# IMM100A register map
Vendor: Infineon; File version: 0.8.0 (Reference Manual v0.8.0)
CPU: CM0 r0p0, little endian, no MPU, no FPU, 2 interrupt priority bits
Registers are 32-bit, read-write, reset 0x0 unless marked. A register's access mark holds for its fields unless they carry their own. Offsets are from the block's base; [hi:lo] are bit positions; lines under a group give offsets from that group; {n}, {i} and the like mark numbered series; 'fields as' and 'values as' point back to an identical list.

## VADC_G0 — Analog to Digital Converter
Base 0x48030400
Same registers: VADC_G1 0x48030800
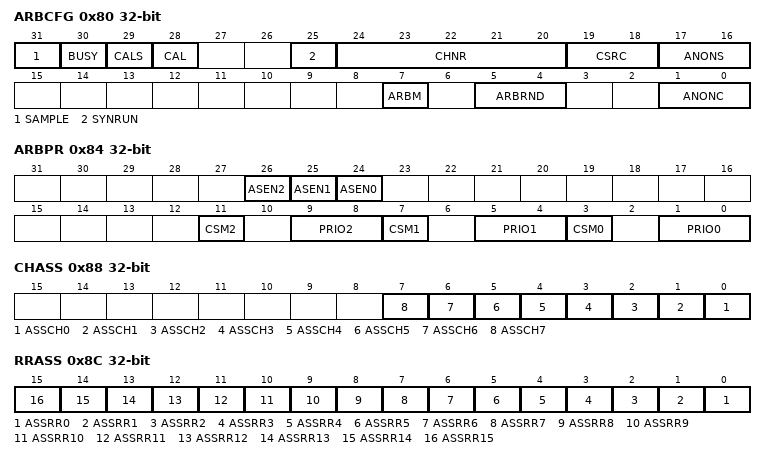
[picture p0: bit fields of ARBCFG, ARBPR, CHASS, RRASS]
0x80 ARBCFG access per field — Arbitration Configuration Register
  [31] SAMPLE ro — Sample Phase Flag
    0=Converting or idle; 1=Input signal is currently sampled
  [30] BUSY ro — Converter Busy Flag
    0=Not busy; 1=Converter is busy with a conversion
  [29] CALS ro — Start-Up Calibration Started
    0=Requested but not yet started; 1=Start-up calibration has begun
  [28] CAL ro — Start-Up Calibration Active Indication
    0=Completed or not yet started; 1=Start-up calibration phase is active (set one clock cycle after setting bit SUCAL)
  [25] SYNRUN ro — Synchronous Conversion Running
    0=Normal conversion or no conversion running; 1=A synchronized conversion is running (cannot be cancelled by higher priority requests!)
  [24:20] CHNR ro — Channel Number
  [19:18] CSRC ro — Currently Converted Request Source
    0=Current/last conversion for request source 0; 1=Current/last conversion for request source 1; 2=Current/last conversion for background source; 3=Current/last conversion for synchronization request (slave converter)
  [17:16] ANONS ro — Analog Converter Control Status
    0=Analog converter off; 2=Slow standby mode; 3=Normal operation (permanently on)
  [7] ARBM rw — Arbitration Mode
    0=The arbiter runs permanently. This setting is required for a synchronization slave (see ) and for equidistant sampling using the signal ARBCNT (see ).; 1=The arbiter only runs if at least one conversion request of an enabled request source is pending. This setting ensures a reproducible latency from an incoming request to the conversion start, if the converter is idle. Synchronized conversions are not supported.
  [5:4] ARBRND rw — Arbitration Round Length
    0=4 arbitration slots per round (tARB = 4 / fADCD); 1=8 arbitration slots per round (tARB = 8 / fADCD); 2=16 arbitration slots per round (tARB = 16 / fADCD); 3=20 arbitration slots per round (tARB = 20 / fADCD)
  [1:0] ANONC rw — Analog Converter Control
0x84 ARBPR — Arbitration Priority Register
  [26] ASEN2 — Arbitration Slot 2 Enable
    0=The corresponding arbitration slot is disabled and considered as empty. Pending conversion requests from the associated request source are disregarded.; 1=The corresponding arbitration slot is enabled. Pending conversion requests from the associated request source are arbitrated.
  [25] ASEN1 — Arbitration Slot 1 Enable
    values as ASEN2
  [24] ASEN0 — Arbitration Slot 0 Enable
    values as ASEN2
  [11] CSM2 — Conversion Start Mode of Request Source x
    0=Wait-for-start mode; 1=Cancel-inject-repeat mode, i.e. this source can cancel conversion of other sources.
  [9:8] PRIO2 — Priority of Request Source x
    0=Lowest priority is selected; 3=Highest priority is selected
  [7] CSM1 — Conversion Start Mode of Request Source x
    values as CSM2
  [5:4] PRIO1 — Priority of Request Source x
    values as PRIO2
  [3] CSM0 — Conversion Start Mode of Request Source x
    values as CSM2
  [1:0] PRIO0 — Priority of Request Source x
    values as PRIO2
0x88 CHASS — Channel Assignment Register
  [all] fields
    0=Channel y can be a background channel converted with lowest priority; 1=Channel y is a priority channel within group x
  [n] ASSCH{n} (n=0..7) — Assignment for Channel {n}
0x8C RRASS — Result Assignment Register
  [all] fields
    0=Result register y can also be written by the background source; 1=Result register y can only be written by sources within group x
  [n] ASSRR{n} (n=0..15) — Assignment for Result Register {n}
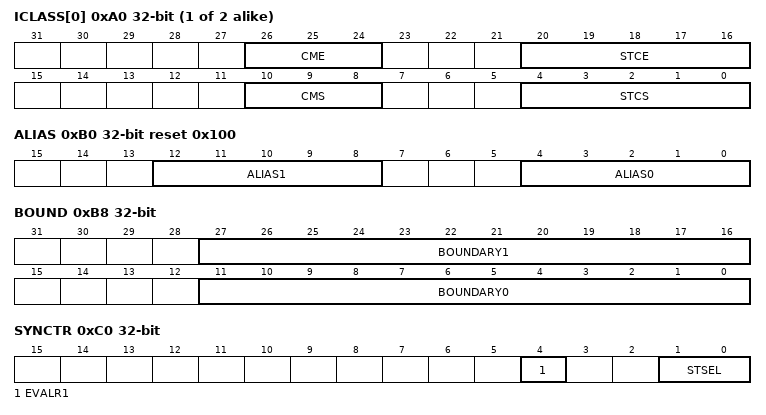
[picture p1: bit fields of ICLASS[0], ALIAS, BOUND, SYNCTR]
{0xA0+4i} ICLASS[{i}] (i=0..1) — Input Class Register 0
  [26:24] CME — Conversion Mode for EMUX Conversions
    0=12-bit conversion; 1=10-bit conversion; 2=8-bit conversion; 5=10-bit fast compare mode
  [20:16] STCE — Sample Time Control for EMUX Conversions
  [10:8] CMS — Conversion Mode for Standard Conversions
    values as CME
  [4:0] STCS — Sample Time Control for Standard Conversions
0xB0 ALIAS reset 0x100
  [12:8] ALIAS1 — Alias Value for CH1 Conversion Requests
  [4:0] ALIAS0 — Alias Value for CH0 Conversion Requests
0xB8 BOUND — Boundary Select Register
  [27:16] BOUNDARY1 — Boundary Value 1 for Limit Checking
  [11:0] BOUNDARY0 — Boundary Value 0 for Limit Checking
0xC0 SYNCTR — Synchronization Control Register
  [4] EVALR1 — Evaluate Ready Input R1
    0=No ready input control; 1=Ready input R1 is considered for the start of a parallel conversion of this conversion group
  [1:0] STSEL — Start Selection
    0=Kernel is synchronization master: Use own bitfield GxARBCFG.ANONC; 1=Kernel is synchronization slave: Control information from input CI1
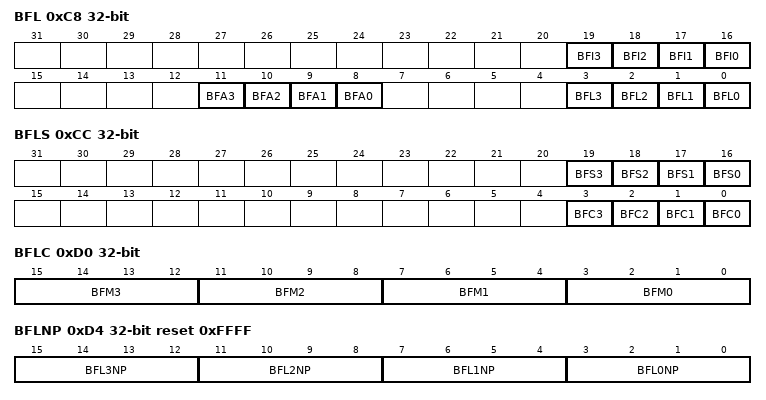
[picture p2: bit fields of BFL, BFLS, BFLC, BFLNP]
0xC8 BFL access per field — Boundary Flag Register
  [n+16] BFI{n} rw (n=0..3) — Boundar{n} Flag y Inversion Control
    0=Use BFLy directly; 1=Invert value and use BFLy
  [n+8] BFA{n} rw (n=0..3) — Boundar{n} Flag y Activation Select
    0=Set boundary flag BFLy if result is above the defined band or compare value, clear if below; 1=Set boundary flag BFLy if result is below the defined band or compare value, clear if above
  [n] BFL{n} ro (n=0..3) — Boundar{n} Flag y
    0=Passive state: result has not yet crossed the activation boundary (see bitfield BFAy), or selected gate signal is inactive, or this boundary flag is disabled; 1=Active state: result has crossed the activation boundary
0xCC BFLS wo — Boundary Flag Software Register
  [n+16] BFS{n} (n=0..3) — Boundar{n} Flag y Set
    0=No action; 1=Set bit BFLy
  [n] BFC{n} (n=0..3) — Boundar{n} Flag y Clear
    0=No action; 1=Clear bit BFLy
0xD0 BFLC — Boundary Flag Control Register
  [all] fields
    0=Disable boundary flag, BFLy is not changed; 1=Always enable boundary flag (follow compare results); 2=Enable boundary flag while gate of source 0 is active, clear BFLy while gate is inactive; 3=Enable boundary flag while gate of source 1 is active, clear BFLy while gate is inactive
  [4n+3:4n] BFM{n} (n=0..3) — Boundary Flag y Mode Control
0xD4 BFLNP reset 0xFFFF — Boundary Flag Node Pointer Register
  [all] fields
    0=Select common bondary flag output 0; 3=Select common bondary flag output 3; 4=Select common service request line C0SR0; 7=Select common service request line C0SR3; 15=Disabled, no common output signal
  [4n+3:4n] BFL{n}NP (n=0..3) — Boundary Flag y Node Pointer
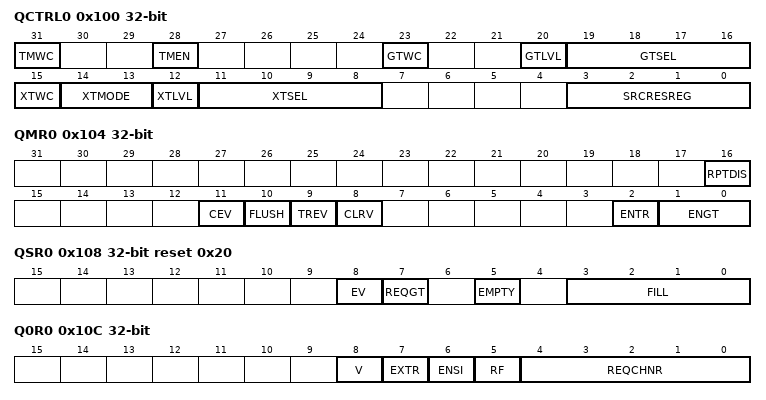
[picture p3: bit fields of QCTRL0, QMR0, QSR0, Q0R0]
0x100 QCTRL0 access per field — Queue 0 Source Control Register
  [31] TMWC wo — Write Control for Timer Mode
    0=No write access to timer mode; 1=Bitfield TMEN can be written
  [28] TMEN rw — Timer Mode Enable
    0=No timer mode: standard gating mechanism can be used; 1=Timer mode for equidistant sampling enabled: standard gating mechanism must be disabled
  [23] GTWC wo — Write Control for Gate Configuration
    0=No write access to gate configuration; 1=Bitfield GTSEL can be written
  [20] GTLVL ro — Gate Input Level
  [19:16] GTSEL rw — Gate Input Selection
  [15] XTWC wo — Write Control for Trigger Configuration
    0=No write access to trigger configuration; 1=Bitfields XTMODE and XTSEL can be written
  [14:13] XTMODE rw — Trigger Operating Mode
    0=No external trigger; 1=Trigger event upon a falling edge; 2=Trigger event upon a rising edge; 3=Trigger event upon any edge
  [12] XTLVL ro — External Trigger Level
  [11:8] XTSEL rw — External Trigger Input Selection
  [3:0] SRCRESREG rw — Source-specific Result Register
    0=Use GxCHCTRy.RESREG to select a group result register; 1=Store result in group result register GxRES1; 15=Store result in group result register GxRES15
0x104 QMR0 access per field — Queue 0 Mode Register
  [16] RPTDIS rw — Repeat Disable
    0=A cancelled conversion is repeated; 1=A cancelled conversion is discarded
  [11] CEV wo — Clear Event Flag
    0=No action; 1=Clear bit EV
  [10] FLUSH wo — Flush Queue
    0=No action; 1=Clear all queue entries (including backup stage) and the event flag EV. The queue contains no more valid entry.
  [9] TREV wo — Trigger Event
    0=No action; 1=Generate a trigger event by software
  [8] CLRV wo — Clear Valid Bit
    0=No action; 1=The next pending valid queue entry in the sequence and the event flag EV are cleared. If there is a valid entry in the queue backup register (QBUR.V = 1), this entry is cleared, otherwise the entry in queue register 0 is cleared.
  [2] ENTR rw — Enable External Trigger
    0=External trigger disabled; 1=The selected edge at the selected trigger input signal REQTR generates the trigger event
  [1:0] ENGT rw — Enable Gate
    0=No conversion requests are issued; 1=Conversion requests are issued if a valid conversion request is pending in the queue 0 register or in the backup register; 2=Conversion requests are issued if a valid conversion request is pending in the queue 0 register or in the backup register and REQGTx = 1; 3=Conversion requests are issued if a valid conversion request is pending in the queue 0 register or in the backup register and REQGTx = 0
0x108 QSR0 ro reset 0x20 — Queue 0 Status Register
  [8] EV — Event Detected
    0=No trigger event; 1=A trigger event has been detected
  [7] REQGT — Request Gate Level
    0=The gate input is low; 1=The gate input is high
  [5] EMPTY — Queue Empty
    0=There are valid entries in the queue (see FILL); 1=No valid entries (queue is empty)
  [3:0] FILL — Filling Level for Queue 2
    0=There is 1 ( if EMPTY = 0) or no (if EMPTY = 1) valid entry in the queue; 1=There are 2 valid entries in the queue; 2=There are 3 valid entries in the queue; 7=There are 8 valid entries in the queue
0x10C Q0R0 ro — Queue 0 Register 0
  [8] V — Request Channel Number Valid
    0=No valid queue entry; 1=The queue entry is valid and leads to a conversion request
  [7] EXTR — External Trigger
    0=A valid queue entry immediately leads to a conversion request; 1=The request handler waits for a trigger event
  [6] ENSI — Enable Source Interrupt
    0=No request source interrupt; 1=A request source event interrupt is generated upon a request source event (related conversion is finished)
  [5] RF — Refill
    0=The request is discarded after the conversion start; 1=The request is automatically refilled into the queue after the conversion start
  [4:0] REQCHNR — Request Channel Number
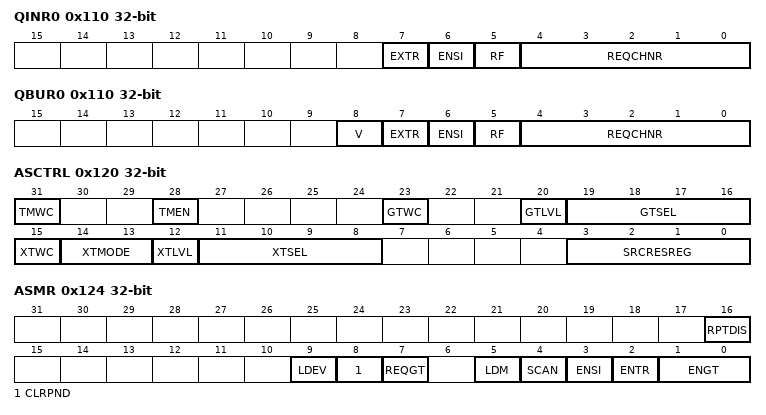
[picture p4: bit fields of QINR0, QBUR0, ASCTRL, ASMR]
0x110 QINR0 wo — Queue 0 Input Register
  [7] EXTR — External Trigger
    0=A valid queue entry immediately leads to a conversion request; 1=A valid queue entry waits for a trigger event to occur before issuing a conversion request
  [6] ENSI — Enable Source Interrupt
    values as Q0R0.ENSI
  [5] RF — Refill
    0=No refill: this queue entry is converted once and then invalidated; 1=Automatic refill: this queue entry is automatically reloaded into QINRx when the related conversion is started
  [4:0] REQCHNR — Request Channel Number
0x110 QBUR0 ro (alternate view of QINR0) — Queue 0 Backup Register
  [8] V — Request Channel Number Valid
    0=Backup register not valid; 1=Backup register contains a valid entry. This will be requested before a valid entry in queue register 0 (stage 0) will be requested.
  [7] EXTR — External Trigger
  [6] ENSI — Enable Source Interrupt
  [5] RF — Refill
  [4:0] REQCHNR — Request Channel Number
0x120 ASCTRL access per field — Autoscan Source Control Register
  fields as QCTRL0
0x124 ASMR access per field — Autoscan Source Mode Register
  [16] RPTDIS rw — Repeat Disable
    values as QMR0.RPTDIS
  [9] LDEV wo — Generate Load Event
    0=No action; 1=A load event is generated
  [8] CLRPND wo — Clear Pending Bits
    0=No action; 1=The bits in register GxASPNDx are cleared
  [7] REQGT ro — Request Gate Level
    0=The gate input is low; 1=The gate input is high
  [5] LDM rw — Autoscan Source Load Event Mode
    0=Overwrite mode: Copy all bits from the select registers to the pending registers upon a load event; 1=Combine mode: Set all pending bits that are set in the select registers upon a load event (logic OR)
  [4] SCAN rw — Autoscan Enable
    0=No autoscan; 1=Autoscan functionality enabled: a request source event automatically generates a load event
  [3] ENSI rw — Enable Source Interrupt
    0=No request source interrupt; 1=A request source interrupt is generated upon a request source event (last pending conversion is finished)
  [2] ENTR rw — Enable External Trigger
    0=External trigger disabled; 1=The selected edge at the selected trigger input signal REQTR generates the load event
  [1:0] ENGT rw — Enable Gate
    0=No conversion requests are issued; 1=Conversion requests are issued if at least one pending bit is set; 2=Conversion requests are issued if at least one pending bit is set and REQGTx = 1; 3=Conversion requests are issued if at least one pending bit is set and REQGTx = 0
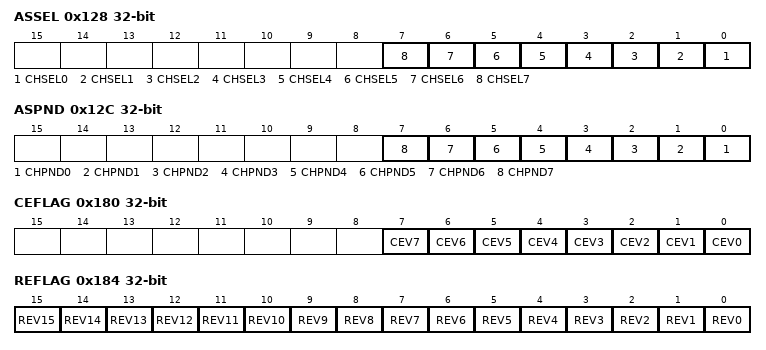
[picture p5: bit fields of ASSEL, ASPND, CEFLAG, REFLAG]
0x128 ASSEL — Autoscan Source Channel Select Register
  [all] fields
    0=Ignore this channel; 1=This channel is part of the scan sequence
  [n] CHSEL{n} (n=0..7) — Channel Selection
0x12C ASPND — Autoscan Source Pending Register
  [all] fields
    0=Ignore this channel; 1=Request conversion of this channel
  [n] CHPND{n} (n=0..7) — Channels Pending
0x180 CEFLAG — Channel Event Flag Register
  [all] fields
    0=No channel event; 1=A channel event has occurred
  [n] CEV{n} (n=0..7) — Channel Event for Channel {n}
0x184 REFLAG — Result Event Flag Register
  [all] fields
    0=No result event; 1=New result was stored in register GxRESy
  [n] REV{n} (n=0..15) — Result Event for Result Register {n}
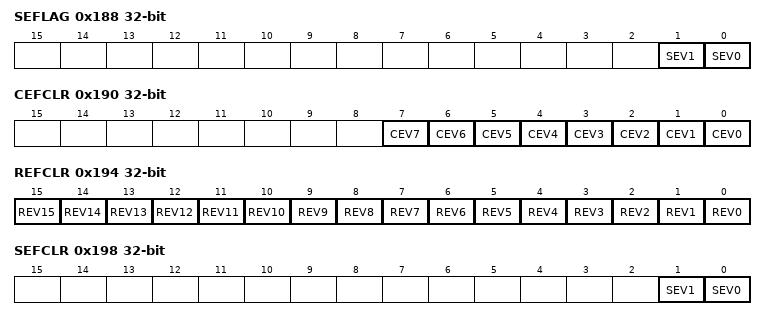
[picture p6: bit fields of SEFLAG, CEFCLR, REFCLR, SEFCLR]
0x188 SEFLAG — Source Event Flag Register
  [1] SEV1 — Source Event 0/1
    0=No source event; 1=A source event has occurred
  [0] SEV0 — Source Event 0/1
    0=No source event; 1=A source event has occurred
0x190 CEFCLR wo — Channel Event Flag Clear Register
  [all] fields
    0=No action; 1=Clear the channel event flag in GxCEFLAG
  [n] CEV{n} (n=0..7) — Clear Channel Event for Channel {n}
0x194 REFCLR wo — Result Event Flag Clear Register
  [all] fields
    0=No action; 1=Clear the result event flag in GxREFLAG
  [n] REV{n} (n=0..15) — Clear Result Event for Result Register {n}
0x198 SEFCLR wo — Source Event Flag Clear Register
  [1] SEV1 — Clear Source Event 0/1
    0=No action; 1=Clear the source event flag in GxSEFLAG
  [0] SEV0 — Clear Source Event 0/1
    0=No action; 1=Clear the source event flag in GxSEFLAG
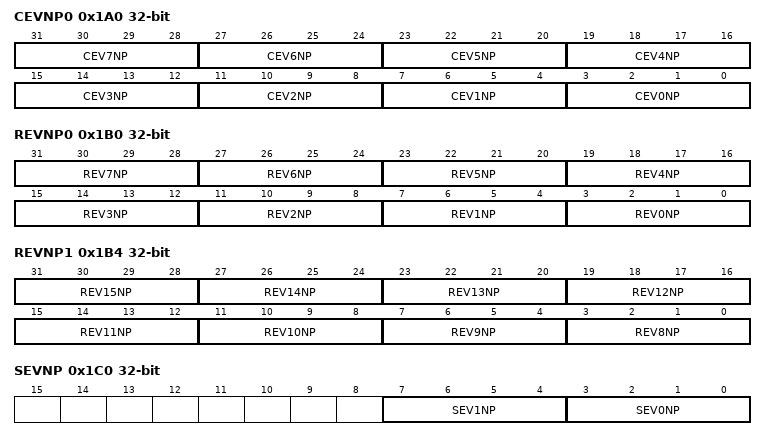
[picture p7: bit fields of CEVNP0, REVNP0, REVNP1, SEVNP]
0x1A0 CEVNP0 — Channel Event Node Pointer Register 0
  [all] fields
    0=Select service request line 0 of group x; 3=Select service request line 3 of group x; 4=Select shared service request line 0; 7=Select shared service request line 3
  [4n+3:4n] CEV{n}NP (n=0..7) — Service Request Node Pointer Channel Event i
0x1B0 REVNP0 — Result Event Node Pointer Register 0
  [all] fields
    values as the fields of CEVNP0
  [4n+3:4n] REV{n}NP (n=0..7) — Service Request Node Pointer Result Event i
0x1B4 REVNP1 — Result Event Node Pointer Register 1
  [all] fields
    values as the fields of CEVNP0
  [4n-29:4n-32] REV{n}NP (n=8..15) — Service Request Node Pointer Result Event i
0x1C0 SEVNP — Source Event Node Pointer Register
  [7:4] SEV1NP — Service Request Node Pointer Source Event i
    values as the fields of CEVNP0
  [3:0] SEV0NP — Service Request Node Pointer Source Event i
    values as the fields of CEVNP0
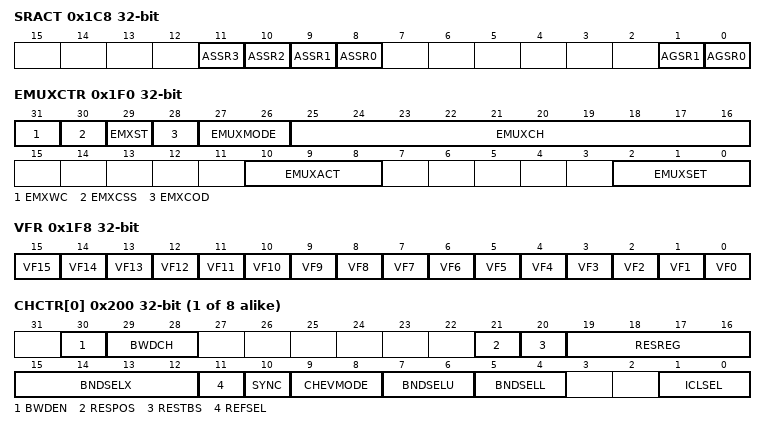
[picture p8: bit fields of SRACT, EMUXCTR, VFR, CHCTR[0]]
0x1C8 SRACT wo — Service Request Software Activation Trigger
  [all] fields
    0=No action; 1=Activate the associated service request line
  [n+8] ASSR{n} (n=0..3) — Activate Shared Service Request Node {n}
  [1] AGSR1 — Activate Group Service Request Node 1
  [0] AGSR0 — Activate Group Service Request Node 0
0x1F0 EMUXCTR access per field — E0ternal Multiplexer Control Register, Group x
  [31] EMXWC wo — Write Control for EMUX Configuration
    0=No write access to EMUX cfg; 1=Bitfields EMXMODE, EMXCOD, EMXST, EMXCSS can be written
  [30] EMXCSS rw — External Multiplexer Channel Selection Style
    0=Channel number: Bitfield EMUXCH selects an arbitrary channel; 1=Channel enable: Each bit of bitfield EMUXCH selects the associated channel for EMUX control
  [29] EMXST rw — External Multiplexer Sample Time Control
    0=Use STCE whenever the setting changes; 1=Use STCE for each conversion of an external channel
  [28] EMXCOD rw — External Multiplexer Coding Scheme
    0=Output the channel number in binary code; 1=Output the channel number in Gray code
  [27:26] EMUXMODE rw — External Multiplexer Mode
    0=Software control (no hardware action); 1=Steady mode (use EMUXSET value); 2=Single-step mode; 3=Sequence mode
  [25:16] EMUXCH rw — External Multiplexer Channel Select
  [10:8] EMUXACT ro — External Multiplexer Actual Selection
  [2:0] EMUXSET rw — External Multiplexer Start Selection
0x1F8 VFR — Valid Flag Register, Group 0
  [all] fields
    0=Read access: No new valid data available Write access: No effect; 1=Read access: Result register x contains valid data and has not yet been read, or bit FCR has been updated Write access: Clear this valid flag and bitfield DRC in register GxRESy (overrides a hardware set action)
  [n] VF{n} (n=0..15) — Valid Flag of Result Register x
{0x200+4i} CHCTR[{i}] (i=0..7) — Channel Ctrl. Reg.
  [30] BWDEN — Broken Wire Detection Enable
    0=Normal operation; 1=Additional preparation phase is enabled
  [29:28] BWDCH — Broken Wire Detection Channel
    0=Select VAREF; 1=Select VAGND
  [21] RESPOS — Result Position
    0=Store results left-aligned; 1=Store results right-aligned
  [20] RESTBS — Result Target for Background Source
    0=Store results in the selected group result register; 1=Store results in the global result register
  [19:16] RESREG — Result Register
    0=Store result in group result register GxRES0; 15=Store result in group result register GxRES15
  [15:12] BNDSELX — BoundaryExtension
    0=Standard mode: select boundaries via BNDSELU/BNDSELL; 1=Use result reg. GxRES1 as upper boundary; 15=Use result reg. GxRES15 as upper boundary
  [11] REFSEL — Reference Input Selection
    0=Standard reference Ground VSS; 1=Alternate reference Ground from CH0
  [10] SYNC — Synchronization Request
    0=No synchroniz. request, standalone operation; 1=Request a synchronized conversion of this channel (only taken into account for a master)
  [9:8] CHEVMODE — Channel Event Mode
    0=Never; 1=NCM: If result is inside the boundary band FCM: If result becomes high (above cmp. val.); 2=NCM: If result is outside the boundary band FCM: If result becomes low (below cmp. val.); 3=NCM: Always (ignore band) FCM: If result switches to either level
  [7:6] BNDSELU — Upper Boundary Select
    0=Use group-specific boundary 0; 1=Use group-specific boundary 1; 2=Use global boundary 0; 3=Use global boundary 1
  [5:4] BNDSELL — Lower Boundary Select
    values as BNDSELU
  [1:0] ICLSEL — Input Class Select
    0=Use group-specific class 0; 1=Use group-specific class 1; 2=Use global class 0; 3=Use global class 1
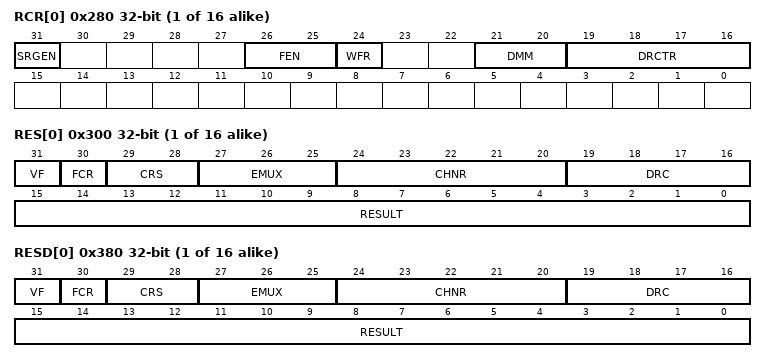
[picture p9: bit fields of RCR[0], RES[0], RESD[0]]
{0x280+4i} RCR[{i}] (i=0..15) — Result Control Reg.
  [31] SRGEN — Service Request Generation Enable
    0=No service request; 1=Service request after a result event
  [26:25] FEN — FIFO Mode Enable
    0=Separate result register; 1=Part of a FIFO structure: copy each new valid result; 2=Maximum mode: copy new result if bigger; 3=Minimum mode: copy new result if smaller
  [24] WFR — Wait-for-Read Mode Enable
    0=Overwrite mode; 1=Wait-for-read mode enabled for this register
  [21:20] DMM — Data Modification Mode
    0=Standard data reduction (accumulation); 1=Result filtering mode; 2=Difference mode
  [19:16] DRCTR — Data Reduction Control
{0x300+4i} RES[{i}] (i=0..15) access per field read-has-side-effects — Result Register
  [31] VF ro — Valid Flag
    0=No new result available; 1=Bitfield RESULT has been updated with new result value and has not yet been read, or bit FCR has been updated
  [30] FCR ro — Fast Compare Result
    0=Signal level was below compare value; 1=Signal level was above compare value
  [29:28] CRS ro — Converted Request Source
    0=Request source 0; 1=Request source 1; 2=Request source 2
  [27:25] EMUX ro — External Multiplexer Setting
  [24:20] CHNR ro — Channel Number
  [19:16] DRC ro — Data Reduction Counter
  [15:0] RESULT rw — Result of Most Recent Conversion
{0x380+4i} RESD[{i}] (i=0..15) ro — Result Register, Debug
  [31] VF — Valid Flag
    values as RES[0].VF
  [30] FCR — Fast Compare Result
    values as RES[0].FCR
  [29:28] CRS — Converted Request Source
    0=Request source 0; 1=Request source 1; 2=Request source 2
  [27:25] EMUX — External Multiplexer Setting
  [24:20] CHNR — Channel Number
  [19:16] DRC — Data Reduction Counter
  [15:0] RESULT — Result of Most Recent Conversion
